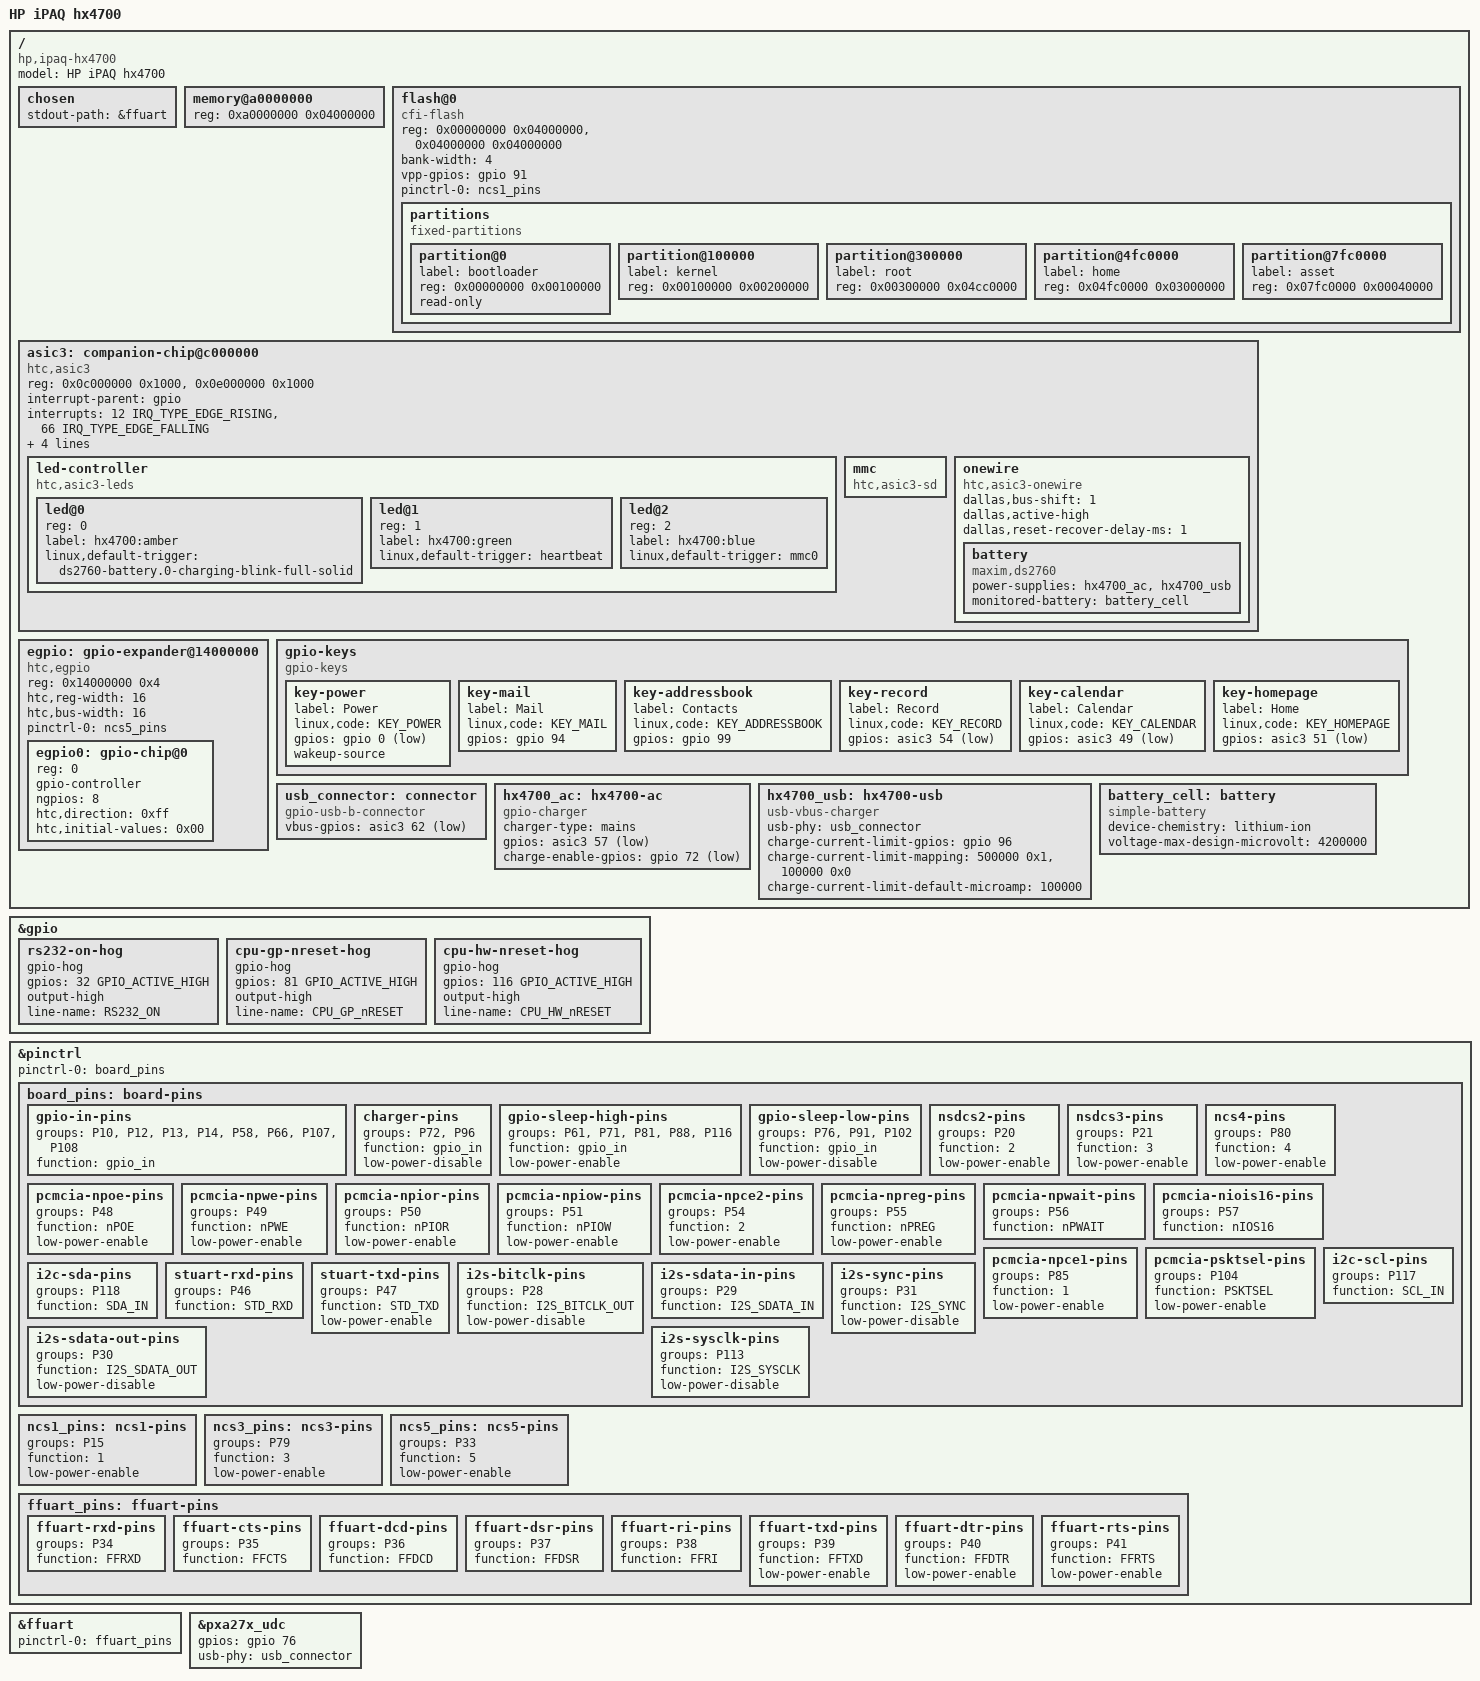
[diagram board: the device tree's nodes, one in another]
// SPDX-License-Identifier: GPL-2.0-only
/*
 * Device tree for the HP iPAQ hx4700.
 *
 * Named pxa270-*: "marvell,pxa270" is the compatible the generic PXA27x
 * devicetree machine matches (arch/arm/mach-pxa/pxa-dt.c).
 *
 * The memory node is a 64 MiB placeholder. The boot loader is ATAGS-only,
 * so the board boots from an appended DTB with ARM_ATAG_DTB_COMPAT, which
 * lets the loader's ATAG_MEM replace the reg property
 * (arch/arm/boot/compressed/atags_to_fdt.c).
 *
 * pxa27x.dtsi has no static memory controller node or chip-select
 * ranges, so the devices on the static chip selects are described at
 * their raw physical addresses: the NOR flash on nCS0 and nCS1, the ASIC3
 * on nCS3 and the EGPIO CPLD on nCS5.
 *
 * Copyright (C) 2026 Koen Kooi
 */

/dts-v1/;

#include <dt-bindings/gpio/gpio.h>
#include <dt-bindings/input/input.h>
#include <dt-bindings/interrupt-controller/irq.h>

#include "pxa27x.dtsi"

/ {
	model = "HP iPAQ hx4700";
	compatible = "hp,ipaq-hx4700", "marvell,pxa270";

	chosen {
		stdout-path = &ffuart;
	};

	memory@a0000000 {
		device_type = "memory";
		reg = <0xa0000000 0x04000000>; /* 64 MiB, ATAG_MEM overrides */
	};

	/*
	 * Two Intel StrataFlash banks of 64 MiB, on nCS0 and nCS1, 32 bits
	 * wide. The program and erase supply is switched by FLASH_VPEN, GPIO91,
	 * which the boot loader and the stock flash code assert around every
	 * erase and program operation and keep low otherwise.
	 *
	 * The partition layout is the one the boot loader and the stock
	 * kernel use.
	 */
	flash@0 {
		compatible = "cfi-flash";
		reg = <0x00000000 0x04000000>,
		      <0x04000000 0x04000000>;
		bank-width = <4>;
		vpp-gpios = <&gpio 91 GPIO_ACTIVE_HIGH>;
		pinctrl-0 = <&ncs1_pins>;
		pinctrl-names = "default";

		partitions {
			compatible = "fixed-partitions";
			#address-cells = <1>;
			#size-cells = <1>;

			partition@0 {
				label = "bootloader";
				reg = <0x00000000 0x00100000>;
				read-only;
			};

			partition@100000 {
				label = "kernel";
				reg = <0x00100000 0x00200000>;
			};

			partition@300000 {
				label = "root";
				reg = <0x00300000 0x04cc0000>;
			};

			partition@4fc0000 {
				label = "home";
				reg = <0x04fc0000 0x03000000>;
			};

			partition@7fc0000 {
				label = "asset";
				reg = <0x07fc0000 0x00040000>;
			};
		};
	};

	/*
	 * ASIC3 on nCS3. The "sd" window is the SD host block, 32 MiB into
	 * the chip select. The chip interrupt is GPIO12 and the SD block
	 * interrupt is GPIO66, a line of the SoC and not of this chip. The
	 * chip reset, ASIC3_nRESET, is GPIO71.
	 */
	asic3: companion-chip@c000000 {
		compatible = "htc,asic3";
		reg = <0x0c000000 0x1000>, <0x0e000000 0x1000>;
		reg-names = "core", "sd";
		interrupt-parent = <&gpio>;
		interrupts = <12 IRQ_TYPE_EDGE_RISING>,
			     <66 IRQ_TYPE_EDGE_FALLING>;
		interrupt-names = "core", "sd";
		reset-gpios = <&gpio 71 GPIO_ACTIVE_LOW>;
		pinctrl-0 = <&ncs3_pins>;
		pinctrl-names = "default";

		gpio-controller;
		#gpio-cells = <2>;
		interrupt-controller;
		#interrupt-cells = <2>;

		/*
		 * The charging trigger of the amber LED is named after the
		 * battery gauge supply and stays idle until that supply exists.
		 */
		led-controller {
			compatible = "htc,asic3-leds";
			#address-cells = <1>;
			#size-cells = <0>;

			led@0 {
				reg = <0>;
				label = "hx4700:amber";
				linux,default-trigger =
					"ds2760-battery.0-charging-blink-full-solid";
			};

			led@1 {
				reg = <1>;
				label = "hx4700:green";
				linux,default-trigger = "heartbeat";
			};

			led@2 {
				reg = <2>;
				label = "hx4700:blue";
				linux,default-trigger = "mmc0";
			};
		};

		/*
		 * Card detect is the register bit of the host, so the node
		 * has no properties. It exists so that the host cell finds
		 * a firmware node.
		 */
		mmc {
			compatible = "htc,asic3-sd";
		};

		/*
		 * The block sits on a 16-bit bus: the registers are at byte
		 * offsets 0, 2, 4, 6 and 8, so the register stride is 1.
		 * The gauge is inside the battery pack and the bus has no
		 * slave with no pack fitted.
		 */
		onewire {
			compatible = "htc,asic3-onewire", "dallas,ds1wm";
			dallas,bus-shift = <1>;
			dallas,active-high;
			dallas,reset-recover-delay-ms = <1>;

			/*
			 * hx4700-ac first: the gauge takes a charge status
			 * from the first supplier that has one.
			 */
			battery {
				compatible = "maxim,ds2760";
				power-supplies = <&hx4700_ac>, <&hx4700_usb>;
				monitored-battery = <&battery_cell>;
			};
		};
	};

	/*
	 * Write-only CPLD on nCS5 that switches the supplies of the CF
	 * socket, the Bluetooth and Wi-Fi modules: eight output lines, all
	 * off until a consumer turns its supply on. Line 4 is CF_3V3_ON and
	 * line 5 is BT_3V3_ON. No input line exists, so the chip has no
	 * interrupt.
	 */
	egpio: gpio-expander@14000000 {
		compatible = "htc,egpio";
		reg = <0x14000000 0x4>;
		htc,reg-width = <16>;
		htc,bus-width = <16>;
		pinctrl-0 = <&ncs5_pins>;
		pinctrl-names = "default";
		#address-cells = <1>;
		#size-cells = <0>;

		egpio0: gpio-chip@0 {
			reg = <0>;
			gpio-controller;
			#gpio-cells = <2>;
			ngpios = <8>;
			htc,direction = <0xff>;
			htc,initial-values = <0x00>;
		};
	};

	/*
	 * Power is the only wakeup source. Record, Calendar and Home are
	 * ASIC3 lines; ASIC3_GPIO(D, n) is 16 * 3 + n.
	 */
	gpio-keys {
		compatible = "gpio-keys";

		key-power {
			label = "Power";
			linux,code = <KEY_POWER>;
			gpios = <&gpio 0 GPIO_ACTIVE_LOW>;
			wakeup-source;
		};

		key-mail {
			label = "Mail";
			linux,code = <KEY_MAIL>;
			gpios = <&gpio 94 GPIO_ACTIVE_HIGH>;
		};

		key-addressbook {
			label = "Contacts";
			linux,code = <KEY_ADDRESSBOOK>;
			gpios = <&gpio 99 GPIO_ACTIVE_HIGH>;
		};

		key-record {
			label = "Record";
			linux,code = <KEY_RECORD>;
			gpios = <&asic3 54 GPIO_ACTIVE_LOW>;
		};

		key-calendar {
			label = "Calendar";
			linux,code = <KEY_CALENDAR>;
			gpios = <&asic3 49 GPIO_ACTIVE_LOW>;
		};

		key-homepage {
			label = "Home";
			linux,code = <KEY_HOMEPAGE>;
			gpios = <&asic3 51 GPIO_ACTIVE_LOW>;
		};
	};

	/*
	 * VBUS sense for the USB device controller: ASIC3 GPIOD14
	 * (offset 62), low with a host attached. The transceiver is
	 * phy-gpio-vbus-usb, not usb-conn-gpio, which matches the same
	 * compatible but has no usb-phy interface.
	 */
	usb_connector: connector {
		compatible = "gpio-usb-b-connector", "usb-b-connector";
		vbus-gpios = <&asic3 62 GPIO_ACTIVE_LOW>;
	};

	/*
	 * The two inputs of the TI BQ24022 charger, which prefers AC by
	 * itself. ASIC3 GPIOD9 is low with the AC adapter plugged in. USB
	 * presence is the connector's VBUS line, so the USB input follows
	 * the transceiver instead of requesting it a second time. ISET2,
	 * GPIO96, selects the USB charge current: 100 mA low, 500 mA high;
	 * the charger ignores it on AC. No charge status line of the
	 * charger is known to reach a GPIO, so neither input reports one.
	 *
	 * The CE input, GPIO72, is low to charge and serves both inputs.
	 * The AC node holds it: gpio-charger asserts it at probe, so the
	 * charger runs from whichever input is present without any action
	 * from userspace, and "inhibit-charge" in the node's
	 * charge_behaviour stops it.
	 */
	hx4700_ac: hx4700-ac {
		compatible = "gpio-charger";
		charger-type = "mains";
		gpios = <&asic3 57 GPIO_ACTIVE_LOW>;
		charge-enable-gpios = <&gpio 72 GPIO_ACTIVE_LOW>;
	};

	hx4700_usb: hx4700-usb {
		compatible = "usb-vbus-charger";
		usb-phy = <&usb_connector>;
		charge-current-limit-gpios = <&gpio 96 GPIO_ACTIVE_HIGH>;
		charge-current-limit-mapping = <500000 0x1>, <100000 0x0>;
		charge-current-limit-default-microamp = <100000>;
	};

	/*
	 * The BQ24022 regulates at 4.2 V, which lets the DS2760 driver tell
	 * a finished charge from a charger that is held off. The pack is
	 * removable, so its capacity stays in the gauge's EEPROM.
	 */
	battery_cell: battery {
		compatible = "simple-battery";
		device-chemistry = "lithium-ion";
		voltage-max-design-microvolt = <4200000>;
	};
};

/*
 * RS232_ON enables the level shifter of the FFUART, the serial console.
 */
&gpio {
	rs232-on-hog {
		gpio-hog;
		gpios = <32 GPIO_ACTIVE_HIGH>;
		output-high;
		line-name = "RS232_ON";
	};

	/* Held high at run time, as by the former mainline board file. */
	cpu-gp-nreset-hog {
		gpio-hog;
		gpios = <81 GPIO_ACTIVE_HIGH>;
		output-high;
		line-name = "CPU_GP_nRESET";
	};

	cpu-hw-nreset-hog {
		gpio-hog;
		gpios = <116 GPIO_ACTIVE_HIGH>;
		output-high;
		line-name = "CPU_HW_nRESET";
	};
};

/*
 * Pin muxing and sleep levels of the PXA pads, those of the former
 * mainline board file. A pad with a consumer node gets its state from that
 * node; the chip selects of the flash, the ASIC3 and the EGPIO CPLD are
 * among them, so that those probes wait for the pin controller. The pads
 * that the board uses without a consumer node (plain GPIOs, nCS4, the SDRAM
 * chip selects, the PC Card strobes, the I2C, STUART and I2S pads) are set
 * by the default state of the pin controller itself when it probes.
 *
 * low-power-disable and low-power-enable select the level an output pad is
 * driven to while the SoC sleeps; a pad without either keeps the sleep
 * level the boot loader programmed. Inputs are not driven in sleep, and a
 * plain GPIO is an output in sleep only while its consumer drives it.
 */
&pinctrl {
	pinctrl-names = "default";
	pinctrl-0 = <&board_pins>;

	board_pins: board-pins {
		/*
		 * GSM_IRQ, ASIC3_IRQ, W3220_IRQ, nWLAN_IRQ, TSC2046_nPENIRQ,
		 * nSDIO_IRQ, DS1WM_IRQ and GSM_READY
		 */
		gpio-in-pins {
			groups = "P10", "P12", "P13", "P14", "P58", "P66", "P107",
				 "P108";
			function = "gpio_in";
		};

		/*
		 * BQ24022_nCHARGE_EN and BQ24022_ISET2: low in sleep, so the
		 * charger stays enabled, at 100 mA from USB. The binding has
		 * no state that keeps the run-time level in sleep.
		 */
		charger-pins {
			groups = "P72", "P96";
			function = "gpio_in";
			low-power-disable;
		};

		/*
		 * W3220_nRESET, ASIC3_nRESET, CPU_GP_nRESET, TSC2046_CS and
		 * CPU_HW_nRESET
		 */
		gpio-sleep-high-pins {
			groups = "P61", "P71", "P81", "P88", "P116";
			function = "gpio_in";
			low-power-enable;
		};

		/*
		 * USBC_PUEN, the D+ pullup, which the device controller drops
		 * before suspend; FLASH_VPEN, high only around a program or
		 * erase operation; SYNAPTICS_POWER_ON
		 */
		gpio-sleep-low-pins {
			groups = "P76", "P91", "P102";
			function = "gpio_in";
			low-power-disable;
		};

		nsdcs2-pins {
			groups = "P20";
			function = "nSDCS<2>";
			low-power-enable;
		};

		nsdcs3-pins {
			groups = "P21";
			function = "nSDCS<3>";
			low-power-enable;
		};

		ncs4-pins {
			groups = "P80";
			function = "nCS<4>";
			low-power-enable;
		};

		/* The CompactFlash socket */
		pcmcia-npoe-pins {
			groups = "P48";
			function = "nPOE";
			low-power-enable;
		};

		pcmcia-npwe-pins {
			groups = "P49";
			function = "nPWE";
			low-power-enable;
		};

		pcmcia-npior-pins {
			groups = "P50";
			function = "nPIOR";
			low-power-enable;
		};

		pcmcia-npiow-pins {
			groups = "P51";
			function = "nPIOW";
			low-power-enable;
		};

		pcmcia-npce2-pins {
			groups = "P54";
			function = "nPCE<2>";
			low-power-enable;
		};

		pcmcia-npreg-pins {
			groups = "P55";
			function = "nPREG";
			low-power-enable;
		};

		pcmcia-npwait-pins {
			groups = "P56";
			function = "nPWAIT";
		};

		pcmcia-niois16-pins {
			groups = "P57";
			function = "nIOS16";
		};

		pcmcia-npce1-pins {
			groups = "P85";
			function = "nPCE<1>";
			low-power-enable;
		};

		pcmcia-psktsel-pins {
			groups = "P104";
			function = "PSKTSEL";
			low-power-enable;
		};

		i2c-scl-pins {
			groups = "P117";
			function = "SCL_IN";
		};

		i2c-sda-pins {
			groups = "P118";
			function = "SDA_IN";
		};

		/* The former IrDA port */
		stuart-rxd-pins {
			groups = "P46";
			function = "STD_RXD";
		};

		stuart-txd-pins {
			groups = "P47";
			function = "STD_TXD";
			low-power-enable;
		};

		i2s-bitclk-pins {
			groups = "P28";
			function = "I2S_BITCLK_OUT";
			low-power-disable;
		};

		i2s-sdata-in-pins {
			groups = "P29";
			function = "I2S_SDATA_IN";
		};

		i2s-sdata-out-pins {
			groups = "P30";
			function = "I2S_SDATA_OUT";
			low-power-disable;
		};

		i2s-sync-pins {
			groups = "P31";
			function = "I2S_SYNC";
			low-power-disable;
		};

		i2s-sysclk-pins {
			groups = "P113";
			function = "I2S_SYSCLK";
			low-power-disable;
		};
	};

	/* The second flash bank */
	ncs1_pins: ncs1-pins {
		groups = "P15";
		function = "nCS<1>";
		low-power-enable;
	};

	ncs3_pins: ncs3-pins {
		groups = "P79";
		function = "nCS<3>";
		low-power-enable;
	};

	ncs5_pins: ncs5-pins {
		groups = "P33";
		function = "nCS<5>";
		low-power-enable;
	};

	ffuart_pins: ffuart-pins {
		ffuart-rxd-pins {
			groups = "P34";
			function = "FFRXD";
		};

		ffuart-cts-pins {
			groups = "P35";
			function = "FFCTS";
		};

		ffuart-dcd-pins {
			groups = "P36";
			function = "FFDCD";
		};

		ffuart-dsr-pins {
			groups = "P37";
			function = "FFDSR";
		};

		ffuart-ri-pins {
			groups = "P38";
			function = "FFRI";
		};

		ffuart-txd-pins {
			groups = "P39";
			function = "FFTXD";
			low-power-enable;
		};

		ffuart-dtr-pins {
			groups = "P40";
			function = "FFDTR";
			low-power-enable;
		};

		ffuart-rts-pins {
			groups = "P41";
			function = "FFRTS";
			low-power-enable;
		};
	};
};

&ffuart {
	pinctrl-0 = <&ffuart_pins>;
	pinctrl-names = "default";

	status = "okay";
};

/*
 * GPIO76 is the D+ pullup of the device controller.
 */
&pxa27x_udc {
	status = "okay";
	gpios = <&gpio 76 GPIO_ACTIVE_HIGH>;
	usb-phy = <&usb_connector>;
};
